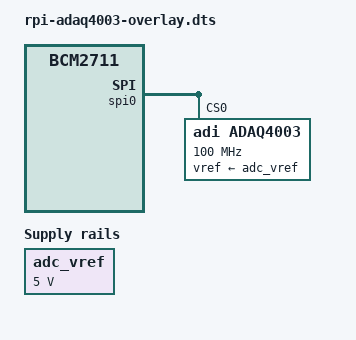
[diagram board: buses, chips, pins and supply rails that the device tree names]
// SPDX-License-Identifier: GPL-2.0-only
// Definitions for Analog Devices ADAQ4003 ADC
/dts-v1/;
/plugin/;

/ {
	compatible = "brcm,bcm2711";

	fragment@0 {
		target-path = "/";
		__overlay__ {
			adc_vref: fixedregulator@0 {
				compatible = "regulator-fixed";
				regulator-name = "fixed-supply";
				regulator-min-microvolt = <5000000>;
				regulator-max-microvolt = <5000000>;
				regulator-boot-on;
			};
		};
	};

	fragment@1 {
		target = <&spi0>;
		__overlay__ {
			#address-cells = <1>;
			#size-cells = <0>;
			status = "okay";

			adaq4003@0 {
				compatible = "adi,adaq4003";
				reg = <0x0>;
				status = "okay";
				spi-max-frequency = <100000000>;
				vref-supply = <&adc_vref>;

				channel@0 {
					reg = <0>;
					diff-channels = <0 1>;
				};
			};
		};
	};
};
